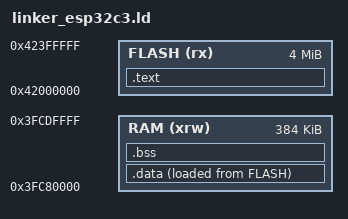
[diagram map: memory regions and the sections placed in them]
ENTRY(Reset_Handler)

MEMORY
{
  FLASH (rx)      : ORIGIN = 0x42000000, LENGTH = 4M
  RAM (xrw)       : ORIGIN = 0x3FC80000, LENGTH = 384K
}

_estack = ORIGIN(RAM) + LENGTH(RAM);

SECTIONS
{
  .text :
  {
    . = ALIGN(4);
    KEEP(*(.text.reset))
    *(.text)
    *(.text.*)
    *(.rodata)
    *(.rodata.*)
    . = ALIGN(4);
    _etext = .;
  } >FLASH

  .data :
  {
    . = ALIGN(4);
    _sdata = .;
    *(.data)
    *(.data.*)
    *(.sdata)
    *(.sdata.*)
    . = ALIGN(4);
    _edata = .;
  } >RAM AT> FLASH

  .bss :
  {
    . = ALIGN(4);
    _sbss = .;
    *(.bss)
    *(.bss.*)
    *(.sbss)
    *(.sbss.*)
    *(COMMON)
    . = ALIGN(4);
    _ebss = .;
  } >RAM
}
